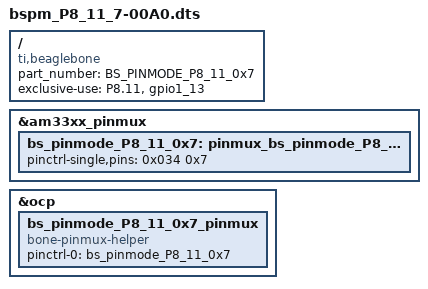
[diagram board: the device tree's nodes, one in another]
/*
 * This is a template-generated file from BoneScript
 */

/*
    # Run on BBB to compile overlay
    dtc -O dtb -o /lib/firmware/bspm_P8_11_7-00A0.dtbo -b 0 -@ /lib/firmware/bspm_P8_11_7-00A0.dts

    # Put this into your /etc/rc.local
    echo bspm_P8_11_7 > /sys/devices/bone_capemgr.?/slots
    echo 45 > /sys/class/gpio/export
*/

/dts-v1/;
/plugin/;

/{
    compatible = "ti,beaglebone", "ti,beaglebone-black";
    part_number = "BS_PINMODE_P8_11_0x7";

    exclusive-use =
        "P8.11",
        "gpio1_13";

    fragment@0 {
        target = <&am33xx_pinmux>;
        __overlay__ {
            bs_pinmode_P8_11_0x7: pinmux_bs_pinmode_P8_11_0x7 {
                pinctrl-single,pins = <0x034 0x7>;
            };
        };
    };

    fragment@1 {
        target = <&ocp>;
        __overlay__ {
            bs_pinmode_P8_11_0x7_pinmux {
                compatible = "bone-pinmux-helper";
                status = "okay";
                pinctrl-names = "default";
                pinctrl-0 = <&bs_pinmode_P8_11_0x7>;
            };
        };
    };
};
